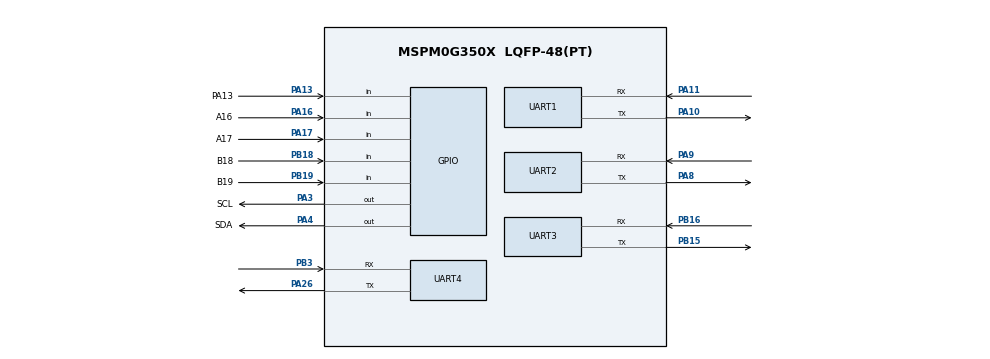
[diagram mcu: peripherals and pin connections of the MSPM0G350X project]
/**
 * @cliArgs --device "MSPM0G350X" --part "Default" --package "LQFP-48(PT)" --product "mspm0_sdk@2.10.00.04"
 * @versions {"tool":"1.26.2+4477"}
 */

/**
 * Import the modules used in this configuration.
 */
const GPIO   = scripting.addModule("/ti/driverlib/GPIO", {}, false);
const GPIO1  = GPIO.addInstance();
const GPIO2  = GPIO.addInstance();
const GPIO3  = GPIO.addInstance();
const SYSCTL = scripting.addModule("/ti/driverlib/SYSCTL");
const UART   = scripting.addModule("/ti/driverlib/UART", {}, false);
const UART1  = UART.addInstance();
const UART2  = UART.addInstance();
const UART3  = UART.addInstance();
const UART4  = UART.addInstance();

/**
 * Write custom configuration values to the imported modules.
 */
const divider9       = system.clockTree["UDIV"];
divider9.divideValue = 2;

const multiplier2         = system.clockTree["PLL_QDIV"];
multiplier2.multiplyValue = 20;

const mux2       = system.clockTree["CANCLKMUX"];
mux2.inputSelect = "CANCLKMUX_PLLCLK1_OUT";

const mux4       = system.clockTree["EXHFMUX"];
mux4.inputSelect = "EXHFMUX_XTAL";

const mux8       = system.clockTree["HSCLKMUX"];
mux8.inputSelect = "HSCLKMUX_SYSPLL0";

const mux12       = system.clockTree["SYSPLLMUX"];
mux12.inputSelect = "zSYSPLLMUX_HFCLK";

const pinFunction4     = system.clockTree["HFXT"];
pinFunction4.inputFreq = 8;
pinFunction4.enable    = true;

GPIO1.$name                              = "IIC";
GPIO1.associatedPins.create(2);
GPIO1.associatedPins[0].$name            = "SCL";
GPIO1.associatedPins[0].initialValue     = "SET";
GPIO1.associatedPins[0].internalResistor = "PULL_UP";
GPIO1.associatedPins[0].pin.$assign      = "PA3";
GPIO1.associatedPins[1].$name            = "SDA";
GPIO1.associatedPins[1].initialValue     = "SET";
GPIO1.associatedPins[1].internalResistor = "PULL_UP";
GPIO1.associatedPins[1].pin.$assign      = "PA4";

const Board = scripting.addModule("/ti/driverlib/Board", {}, false);

GPIO2.$name                              = "KEY";
GPIO2.associatedPins[0].$name            = "PA13";
GPIO2.associatedPins[0].direction        = "INPUT";
GPIO2.associatedPins[0].internalResistor = "PULL_UP";
GPIO2.associatedPins[0].pin.$assign      = "PA13";

GPIO3.$name                              = "IR";
GPIO3.associatedPins.create(4);
GPIO3.associatedPins[0].$name            = "A17";
GPIO3.associatedPins[0].direction        = "INPUT";
GPIO3.associatedPins[0].internalResistor = "PULL_UP";
GPIO3.associatedPins[0].pin.$assign      = "PA17";
GPIO3.associatedPins[1].$name            = "B18";
GPIO3.associatedPins[1].direction        = "INPUT";
GPIO3.associatedPins[1].internalResistor = "PULL_UP";
GPIO3.associatedPins[1].pin.$assign      = "PB18";
GPIO3.associatedPins[2].$name            = "B19";
GPIO3.associatedPins[2].direction        = "INPUT";
GPIO3.associatedPins[2].internalResistor = "PULL_UP";
GPIO3.associatedPins[2].pin.$assign      = "PB19";
GPIO3.associatedPins[3].$name            = "A16";
GPIO3.associatedPins[3].direction        = "INPUT";
GPIO3.associatedPins[3].internalResistor = "PULL_UP";
GPIO3.associatedPins[3].pin.$assign      = "PA16";

SYSCTL.clockTreeEn           = true;
SYSCTL.forceDefaultClkConfig = true;
SYSCTL.validateClkStatus     = true;

UART1.$name                             = "UART_0";
UART1.enabledInterrupts                 = ["DMA_DONE_TX","EOT_DONE","RX"];
UART1.enableFIFO                        = true;
UART1.rxFifoThreshold                   = "DL_UART_RX_FIFO_LEVEL_ONE_ENTRY";
UART1.rxTimeoutValue                    = 10;
UART1.enabledDMATXTriggers              = "DL_UART_DMA_INTERRUPT_TX";
UART1.peripheral.$assign                = "UART0";
UART1.peripheral.rxPin.$assign          = "PA11";
UART1.peripheral.txPin.$assign          = "PA10";
UART1.txPinConfig.$name                 = "ti_driverlib_gpio_GPIOPinGeneric0";
UART1.rxPinConfig.$name                 = "ti_driverlib_gpio_GPIOPinGeneric1";
UART1.DMA_CHANNEL_TX.$name              = "DMA_CH0";
UART1.DMA_CHANNEL_TX.addressMode        = "b2f";
UART1.DMA_CHANNEL_TX.srcLength          = "BYTE";
UART1.DMA_CHANNEL_TX.dstLength          = "BYTE";
UART1.DMA_CHANNEL_TX.enableInterrupt    = true;
UART1.DMA_CHANNEL_TX.peripheral.$assign = "DMA_CH0";

UART2.$name                             = "UART_1";
UART2.targetBaudRate                    = 115200;
UART2.enabledInterrupts                 = ["DMA_DONE_TX","EOT_DONE","RX"];
UART2.enableFIFO                        = true;
UART2.rxFifoThreshold                   = "DL_UART_RX_FIFO_LEVEL_ONE_ENTRY";
UART2.rxTimeoutValue                    = 10;
UART2.enabledDMATXTriggers              = "DL_UART_DMA_INTERRUPT_TX";
UART2.peripheral.$assign                = "UART1";
UART2.peripheral.rxPin.$assign          = "PA9";
UART2.peripheral.txPin.$assign          = "PA8";
UART2.txPinConfig.$name                 = "ti_driverlib_gpio_GPIOPinGeneric2";
UART2.rxPinConfig.$name                 = "ti_driverlib_gpio_GPIOPinGeneric3";
UART2.DMA_CHANNEL_TX.$name              = "DMA_CH1";
UART2.DMA_CHANNEL_TX.addressMode        = "b2f";
UART2.DMA_CHANNEL_TX.srcLength          = "BYTE";
UART2.DMA_CHANNEL_TX.dstLength          = "BYTE";
UART2.DMA_CHANNEL_TX.enableInterrupt    = true;
UART2.DMA_CHANNEL_TX.peripheral.$assign = "DMA_CH1";

UART3.$name                             = "UART_2";
UART3.enabledInterrupts                 = ["DMA_DONE_TX","EOT_DONE","RX"];
UART3.enableFIFO                        = true;
UART3.rxFifoThreshold                   = "DL_UART_RX_FIFO_LEVEL_ONE_ENTRY";
UART3.rxTimeoutValue                    = 10;
UART3.enabledDMATXTriggers              = "DL_UART_DMA_INTERRUPT_TX";
UART3.peripheral.$assign                = "UART2";
UART3.peripheral.rxPin.$assign          = "PB16";
UART3.peripheral.txPin.$assign          = "PB15";
UART3.txPinConfig.$name                 = "ti_driverlib_gpio_GPIOPinGeneric4";
UART3.rxPinConfig.$name                 = "ti_driverlib_gpio_GPIOPinGeneric5";
UART3.DMA_CHANNEL_TX.$name              = "DMA_CH2";
UART3.DMA_CHANNEL_TX.addressMode        = "b2f";
UART3.DMA_CHANNEL_TX.srcLength          = "BYTE";
UART3.DMA_CHANNEL_TX.dstLength          = "BYTE";
UART3.DMA_CHANNEL_TX.enableInterrupt    = true;
UART3.DMA_CHANNEL_TX.peripheral.$assign = "DMA_CH2";

UART4.$name                             = "UART_3";
UART4.enabledInterrupts                 = ["DMA_DONE_TX","EOT_DONE","RX"];
UART4.enabledDMATXTriggers              = "DL_UART_DMA_INTERRUPT_TX";
UART4.enableFIFO                        = true;
UART4.rxFifoThreshold                   = "DL_UART_RX_FIFO_LEVEL_ONE_ENTRY";
UART4.rxTimeoutValue                    = 10;
UART4.peripheral.$assign                = "UART3";
UART4.peripheral.rxPin.$assign          = "PB3";
UART4.peripheral.txPin.$assign          = "PA26";
UART4.txPinConfig.$name                 = "ti_driverlib_gpio_GPIOPinGeneric6";
UART4.rxPinConfig.$name                 = "ti_driverlib_gpio_GPIOPinGeneric7";
UART4.DMA_CHANNEL_TX.$name              = "DMA_CH3";
UART4.DMA_CHANNEL_TX.addressMode        = "b2f";
UART4.DMA_CHANNEL_TX.srcLength          = "BYTE";
UART4.DMA_CHANNEL_TX.dstLength          = "BYTE";
UART4.DMA_CHANNEL_TX.enableInterrupt    = true;
UART4.DMA_CHANNEL_TX.peripheral.$assign = "DMA_CH3";

/**
 * Pinmux solution for unlocked pins/peripherals. This ensures that minor changes to the automatic solver in a future
 * version of the tool will not impact the pinmux you originally saw.  These lines can be completely deleted in order to
 * re-solve from scratch.
 */
pinFunction4.peripheral.$suggestSolution           = "SYSCTL";
pinFunction4.peripheral.hfxInPin.$suggestSolution  = "PA5";
pinFunction4.peripheral.hfxOutPin.$suggestSolution = "PA6";
Board.peripheral.$suggestSolution                  = "DEBUGSS";
Board.peripheral.swclkPin.$suggestSolution         = "PA20";
Board.peripheral.swdioPin.$suggestSolution         = "PA19";
